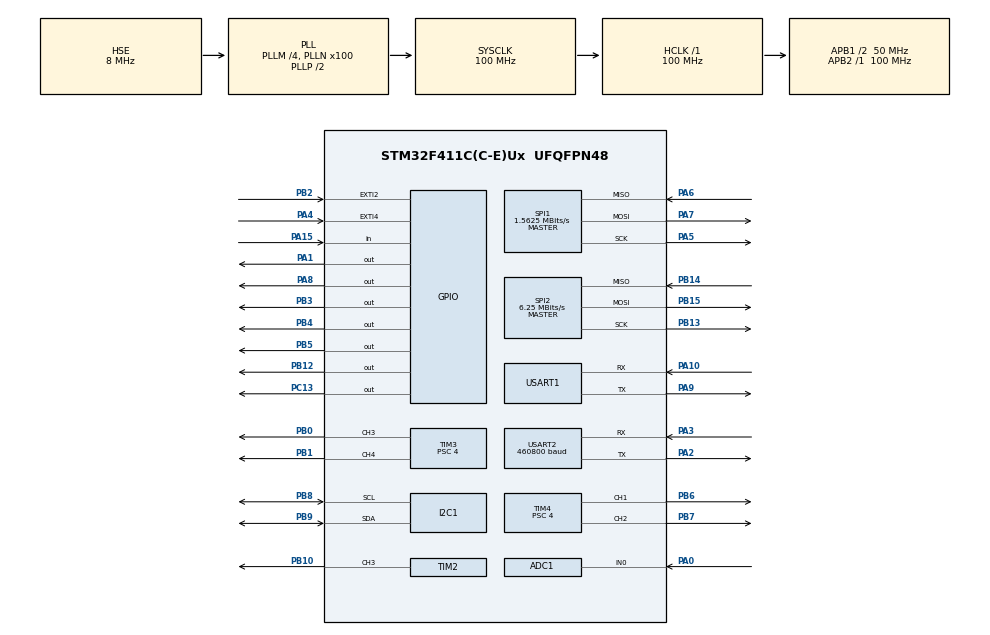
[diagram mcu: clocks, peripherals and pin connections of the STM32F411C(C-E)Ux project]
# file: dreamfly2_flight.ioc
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ADC1.Channel-0\#ChannelRegularConversion=ADC_CHANNEL_0
ADC1.InjNumberOfConversion=0
ADC1.NbrOfConversionFlag=1
ADC1.Rank-0\#ChannelRegularConversion=1
ADC1.SamplingTime-0\#ChannelRegularConversion=ADC_SAMPLETIME_144CYCLES
ADC1.master=1
Dma.Request0=TIM2_CH3/UP
Dma.Request1=USART1_TX
Dma.Request2=USART1_RX
Dma.Request3=USART2_TX
Dma.Request4=USART2_RX
Dma.TIM2_CH3/UP.0.Direction=DMA_MEMORY_TO_PERIPH
Dma.TIM2_CH3/UP.0.FIFOMode=DMA_FIFOMODE_DISABLE
Dma.TIM2_CH3/UP.0.Instance=DMA1_Stream1
Dma.TIM2_CH3/UP.0.MemDataAlignment=DMA_MDATAALIGN_WORD
Dma.TIM2_CH3/UP.0.MemInc=DMA_MINC_ENABLE
Dma.TIM2_CH3/UP.0.Mode=DMA_NORMAL
Dma.TIM2_CH3/UP.0.PeriphDataAlignment=DMA_PDATAALIGN_WORD
Dma.TIM2_CH3/UP.0.PeriphInc=DMA_PINC_DISABLE
Dma.TIM2_CH3/UP.0.Priority=DMA_PRIORITY_LOW
Dma.USART1_RX.2.Direction=DMA_PERIPH_TO_MEMORY
Dma.USART1_RX.2.FIFOMode=DMA_FIFOMODE_DISABLE
Dma.USART1_RX.2.Instance=DMA2_Stream2
Dma.USART1_RX.2.MemDataAlignment=DMA_MDATAALIGN_BYTE
Dma.USART1_RX.2.MemInc=DMA_MINC_ENABLE
Dma.USART1_RX.2.Mode=DMA_NORMAL
Dma.USART1_RX.2.PeriphDataAlignment=DMA_PDATAALIGN_BYTE
Dma.USART1_RX.2.PeriphInc=DMA_PINC_DISABLE
Dma.USART1_RX.2.Priority=DMA_PRIORITY_LOW
Dma.USART1_TX.1.Direction=DMA_MEMORY_TO_PERIPH
Dma.USART1_TX.1.FIFOMode=DMA_FIFOMODE_DISABLE
Dma.USART1_TX.1.Instance=DMA2_Stream7
Dma.USART1_TX.1.MemDataAlignment=DMA_MDATAALIGN_BYTE
Dma.USART1_TX.1.MemInc=DMA_MINC_ENABLE
Dma.USART1_TX.1.Mode=DMA_NORMAL
Dma.USART1_TX.1.PeriphDataAlignment=DMA_PDATAALIGN_BYTE
Dma.USART1_TX.1.PeriphInc=DMA_PINC_DISABLE
Dma.USART1_TX.1.Priority=DMA_PRIORITY_LOW
Dma.USART2_RX.4.Direction=DMA_PERIPH_TO_MEMORY
Dma.USART2_RX.4.FIFOMode=DMA_FIFOMODE_DISABLE
Dma.USART2_RX.4.Instance=DMA1_Stream5
Dma.USART2_RX.4.MemDataAlignment=DMA_MDATAALIGN_BYTE
Dma.USART2_RX.4.MemInc=DMA_MINC_ENABLE
Dma.USART2_RX.4.Mode=DMA_NORMAL
Dma.USART2_RX.4.PeriphDataAlignment=DMA_PDATAALIGN_BYTE
Dma.USART2_RX.4.PeriphInc=DMA_PINC_DISABLE
Dma.USART2_RX.4.Priority=DMA_PRIORITY_LOW
Dma.USART2_TX.3.Direction=DMA_MEMORY_TO_PERIPH
Dma.USART2_TX.3.FIFOMode=DMA_FIFOMODE_DISABLE
Dma.USART2_TX.3.Instance=DMA1_Stream6
Dma.USART2_TX.3.MemDataAlignment=DMA_MDATAALIGN_BYTE
Dma.USART2_TX.3.MemInc=DMA_MINC_ENABLE
Dma.USART2_TX.3.Mode=DMA_NORMAL
Dma.USART2_TX.3.PeriphDataAlignment=DMA_PDATAALIGN_BYTE
Dma.USART2_TX.3.PeriphInc=DMA_PINC_DISABLE
Dma.USART2_TX.3.Priority=DMA_PRIORITY_LOW
FREERTOS.Tasks01=flight_systems,16,256,flight_system_task_entry,As weak,NULL,Dynamic,NULL,NULL;flight_control,40,256,flight_control_task_entry,As weak,NULL,Dynamic,NULL,NULL;flight_sensor,24,256,flight_sensor_task_entry,As weak,NULL,Dynamic,NULL,NULL;flight_debug,8,512,flight_debug_task_entry,As weak,NULL,Dynamic,NULL,NULL;flight_link,32,256,flight_link_task_entry,As weak,NULL,Dynamic,NULL,NULL
I2C1.I2C_Mode=I2C_Fast
Mcu.Family=STM32F4
Mcu.Name=STM32F411C(C-E)Ux
Mcu.Package=UFQFPN48
NVIC.DMA1_Stream1_IRQn=true\:5\:0\:false\:false\:true\:true\:false\:true\:true
NVIC.DMA1_Stream5_IRQn=true\:5\:0\:false\:false\:true\:true\:false\:true\:true
NVIC.DMA1_Stream6_IRQn=true\:5\:0\:false\:false\:true\:true\:false\:true\:true
NVIC.DMA2_Stream2_IRQn=true\:5\:0\:false\:false\:true\:true\:false\:true\:true
NVIC.DMA2_Stream7_IRQn=true\:5\:0\:false\:false\:true\:true\:false\:true\:true
NVIC.EXTI2_IRQn=true\:5\:0\:false\:false\:true\:true\:true\:true\:true
NVIC.EXTI4_IRQn=true\:5\:0\:false\:false\:true\:true\:true\:true\:true
NVIC.PriorityGroup=NVIC_PRIORITYGROUP_4
NVIC.TIM1_TRG_COM_TIM11_IRQn=true\:15\:0\:false\:false\:true\:false\:false\:true\:true
NVIC.TimeBase=TIM1_TRG_COM_TIM11_IRQn
NVIC.TimeBaseIP=TIM11
NVIC.USART1_IRQn=true\:5\:0\:false\:false\:true\:true\:true\:true\:true
NVIC.USART2_IRQn=true\:5\:0\:false\:false\:true\:true\:true\:true\:true
PA0-WKUP.Signal=ADCx_IN0
PA1.PinState=GPIO_PIN_SET
PA1.Signal=GPIO_Output
PA10.Mode=Asynchronous
PA10.Signal=USART1_RX
PA13.Mode=Serial_Wire
PA13.Signal=SYS_JTMS-SWDIO
PA14.Mode=Serial_Wire
PA14.Signal=SYS_JTCK-SWCLK
PA15.Signal=GPIO_Input
PA2.Mode=Asynchronous
PA2.Signal=USART2_TX
PA3.Mode=Asynchronous
PA3.Signal=USART2_RX
PA4.Signal=GPXTI4
PA5.Mode=Full_Duplex_Master
PA5.Signal=SPI1_SCK
PA6.Mode=Full_Duplex_Master
PA6.Signal=SPI1_MISO
PA7.Mode=Full_Duplex_Master
PA7.Signal=SPI1_MOSI
PA8.PinState=GPIO_PIN_RESET
PA8.Signal=GPIO_Output
PA9.Mode=Asynchronous
PA9.Signal=USART1_TX
PB0.Signal=S_TIM3_CH3
PB1.Signal=S_TIM3_CH4
PB10.GPIO_ModeDefaultPP=GPIO_MODE_AF_PP
PB10.GPIO_Speed=GPIO_SPEED_FREQ_HIGH
PB10.Signal=S_TIM2_CH3
PB12.PinState=GPIO_PIN_SET
PB12.Signal=GPIO_Output
PB13.Mode=Full_Duplex_Master
PB13.Signal=SPI2_SCK
PB14.Mode=Full_Duplex_Master
PB14.Signal=SPI2_MISO
PB15.Mode=Full_Duplex_Master
PB15.Signal=SPI2_MOSI
PB2.GPIO_ModeDefaultEXTI=GPIO_MODE_IT_FALLING
PB2.GPIO_PuPd=GPIO_PULLUP
PB2.Signal=GPXTI2
PB3.GPIO_ModeDefaultOutputPP=GPIO_MODE_OUTPUT_OD
PB3.GPIO_PuPd=GPIO_NOPULL
PB3.PinState=GPIO_PIN_SET
PB3.Signal=GPIO_Output
PB4.GPIO_ModeDefaultOutputPP=GPIO_MODE_OUTPUT_OD
PB4.GPIO_PuPd=GPIO_NOPULL
PB4.GPIO_Speed=GPIO_SPEED_FREQ_VERY_HIGH
PB4.PinState=GPIO_PIN_SET
PB4.Signal=GPIO_Output
PB5.GPIO_ModeDefaultOutputPP=GPIO_MODE_OUTPUT_OD
PB5.GPIO_PuPd=GPIO_NOPULL
PB5.GPIO_Speed=GPIO_SPEED_FREQ_VERY_HIGH
PB5.PinState=GPIO_PIN_SET
PB5.Signal=GPIO_Output
PB6.Signal=S_TIM4_CH1
PB7.Signal=S_TIM4_CH2
PB8.Mode=I2C
PB8.Signal=I2C1_SCL
PB9.Mode=I2C
PB9.Signal=I2C1_SDA
PC13-ANTI_TAMP.Signal=GPIO_Output
PH0\ -\ OSC_IN.Mode=HSE-External-Oscillator
PH0\ -\ OSC_IN.Signal=RCC_OSC_IN
PH1\ -\ OSC_OUT.Mode=HSE-External-Oscillator
PH1\ -\ OSC_OUT.Signal=RCC_OSC_OUT
ProjectManager.HeapSize=0x200
ProjectManager.StackSize=0x400
ProjectManager.TargetToolchain=CMake
RCC.48MHZClocksFreq_Value=50000000
RCC.AHBFreq_Value=100000000
RCC.APB1CLKDivider=RCC_HCLK_DIV2
RCC.APB1Freq_Value=50000000
RCC.APB1TimFreq_Value=100000000
RCC.APB2Freq_Value=100000000
RCC.APB2TimFreq_Value=100000000
RCC.CortexFreq_Value=100000000
RCC.HCLKFreq_Value=100000000
RCC.HSE_VALUE=8000000
RCC.HSI_VALUE=16000000
RCC.LSE_VALUE=32768
RCC.PLLM=4
RCC.PLLN=100
RCC.PLLSourceVirtual=RCC_PLLSOURCE_HSE
RCC.SYSCLKFreq_VALUE=100000000
RCC.SYSCLKSource=RCC_SYSCLKSOURCE_PLLCLK
RCC.VCOOutputFreq_Value=200000000
SH.ADCx_IN0.0=ADC1_IN0,IN0
SH.S_TIM2_CH3.0=TIM2_CH3,PWM Generation3 CH3
SH.S_TIM3_CH3.0=TIM3_CH3,PWM Generation3 CH3
SH.S_TIM3_CH4.0=TIM3_CH4,PWM Generation4 CH4
SH.S_TIM4_CH1.0=TIM4_CH1,PWM Generation1 CH1
SH.S_TIM4_CH2.0=TIM4_CH2,PWM Generation2 CH2
SPI1.BaudRatePrescaler=SPI_BAUDRATEPRESCALER_64
SPI1.CLKPhase=SPI_PHASE_1EDGE
SPI1.CLKPolarity=SPI_POLARITY_LOW
SPI1.CalculateBaudRate=1.5625 MBits/s
SPI1.Direction=SPI_DIRECTION_2LINES
SPI1.Mode=SPI_MODE_MASTER
SPI1.VirtualType=VM_MASTER
SPI2.BaudRatePrescaler=SPI_BAUDRATEPRESCALER_8
SPI2.CalculateBaudRate=6.25 MBits/s
SPI2.Direction=SPI_DIRECTION_2LINES
SPI2.Mode=SPI_MODE_MASTER
SPI2.VirtualType=VM_MASTER
TIM2.Channel-PWM\ Generation3\ CH3=TIM_CHANNEL_3
TIM2.Period=124
TIM3.AutoReloadPreload=TIM_AUTORELOAD_PRELOAD_ENABLE
TIM3.Channel-PWM\ Generation3\ CH3=TIM_CHANNEL_3
TIM3.Channel-PWM\ Generation4\ CH4=TIM_CHANNEL_4
TIM3.Period=999
TIM3.Prescaler=4
TIM4.AutoReloadPreload=TIM_AUTORELOAD_PRELOAD_ENABLE
TIM4.Channel-PWM\ Generation1\ CH1=TIM_CHANNEL_1
TIM4.Channel-PWM\ Generation2\ CH2=TIM_CHANNEL_2
TIM4.Period=999
TIM4.Prescaler=4
USART1.VirtualMode=VM_ASYNC
USART2.BaudRate=460800
USART2.VirtualMode=VM_ASYNC
VP_FREERTOS_VS_CMSIS_V2.Mode=CMSIS_V2
VP_SYS_VS_tim11.Mode=TIM11
VP_TIM2_VS_ClockSourceINT.Mode=Internal
VP_TIM3_VS_ClockSourceINT.Mode=Internal
VP_TIM4_VS_ClockSourceINT.Mode=Internal
board=custom

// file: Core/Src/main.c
/* USER CODE BEGIN Header */
/**
  ******************************************************************************
  * @file           : main.c
  * @brief          : Main program body
  ******************************************************************************
  * @attention
  *
  * Copyright (c) 2026 STMicroelectronics.
  * All rights reserved.
  *
  * This software is licensed under terms that can be found in the LICENSE file
  * in the root directory of this software component.
  * If no LICENSE file comes with this software, it is provided AS-IS.
  *
  ******************************************************************************
  */
/* USER CODE END Header */
#include "main.h"
#include "cmsis_os.h"
#include "adc.h"
#include "dma.h"
#include "i2c.h"
#include "spi.h"
#include "tim.h"
#include "usart.h"
#include "gpio.h"

void SystemClock_Config(void);
void MX_FREERTOS_Init(void);

int main(void)
{

  /* MCU Configuration--------------------------------------------------------*/

  /* Reset of all peripherals, Initializes the Flash interface and the Systick. */
  HAL_Init();

  /* Configure the system clock */
  SystemClock_Config();

  /* Initialize all configured peripherals */
  MX_GPIO_Init();
  MX_DMA_Init();
  MX_USART1_UART_Init();
  MX_USART2_UART_Init();
  MX_ADC1_Init();
  MX_I2C1_Init();
  MX_TIM2_Init();
  MX_TIM3_Init();
  MX_TIM4_Init();
  MX_SPI2_Init();
  MX_SPI1_Init();

  /* Init scheduler */
  osKernelInitialize();  /* Call init function for freertos objects (in cmsis_os2.c) */
  MX_FREERTOS_Init();

  /* Start scheduler */
  osKernelStart();

  /* We should never get here as control is now taken by the scheduler */

  /* Infinite loop */
    while (1)
    {

    }
}

void SystemClock_Config(void)
{
  RCC_OscInitTypeDef RCC_OscInitStruct = {0};
  RCC_ClkInitTypeDef RCC_ClkInitStruct = {0};

  /** Configure the main internal regulator output voltage
  */
  __HAL_RCC_PWR_CLK_ENABLE();
  __HAL_PWR_VOLTAGESCALING_CONFIG(PWR_REGULATOR_VOLTAGE_SCALE1);

  /** Initializes the RCC Oscillators according to the specified parameters
  * in the RCC_OscInitTypeDef structure.
  */
  RCC_OscInitStruct.OscillatorType = RCC_OSCILLATORTYPE_HSE;
  RCC_OscInitStruct.HSEState = RCC_HSE_ON;
  RCC_OscInitStruct.PLL.PLLState = RCC_PLL_ON;
  RCC_OscInitStruct.PLL.PLLSource = RCC_PLLSOURCE_HSE;
  RCC_OscInitStruct.PLL.PLLM = 4;
  RCC_OscInitStruct.PLL.PLLN = 100;
  RCC_OscInitStruct.PLL.PLLP = RCC_PLLP_DIV2;
  RCC_OscInitStruct.PLL.PLLQ = 4;
  if (HAL_RCC_OscConfig(&RCC_OscInitStruct) != HAL_OK)
  {
    Error_Handler();
  }

  /** Initializes the CPU, AHB and APB buses clocks
  */
  RCC_ClkInitStruct.ClockType = RCC_CLOCKTYPE_HCLK|RCC_CLOCKTYPE_SYSCLK
                              |RCC_CLOCKTYPE_PCLK1|RCC_CLOCKTYPE_PCLK2;
  RCC_ClkInitStruct.SYSCLKSource = RCC_SYSCLKSOURCE_PLLCLK;
  RCC_ClkInitStruct.AHBCLKDivider = RCC_SYSCLK_DIV1;
  RCC_ClkInitStruct.APB1CLKDivider = RCC_HCLK_DIV2;
  RCC_ClkInitStruct.APB2CLKDivider = RCC_HCLK_DIV1;

  if (HAL_RCC_ClockConfig(&RCC_ClkInitStruct, FLASH_LATENCY_3) != HAL_OK)
  {
    Error_Handler();
  }
}

void HAL_TIM_PeriodElapsedCallback(TIM_HandleTypeDef *htim)
{
  if (htim->Instance == TIM11)
  {
    HAL_IncTick();
  }
}

void Error_Handler(void)
{
    __disable_irq();
    while (1)
    {
    }
}

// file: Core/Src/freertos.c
/* USER CODE BEGIN Header */
/**
  ******************************************************************************
  * File Name          : freertos.c
  * Description        : Code for freertos applications
  ******************************************************************************
  * @attention
  *
  * Copyright (c) 2026 STMicroelectronics.
  * All rights reserved.
  *
  * This software is licensed under terms that can be found in the LICENSE file
  * in the root directory of this software component.
  * If no LICENSE file comes with this software, it is provided AS-IS.
  *
  ******************************************************************************
  */
/* USER CODE END Header */

#include "FreeRTOS.h"
#include "task.h"
#include "main.h"
#include "cmsis_os.h"

/* USER CODE BEGIN Includes */
#include "led.h"
/* USER CODE END Includes */

/* Definitions for flight_systems */
osThreadId_t flight_systemsHandle;
const osThreadAttr_t flight_systems_attributes = {
  .name = "flight_systems",
  .stack_size = 256 * 4,
  .priority = (osPriority_t) osPriorityBelowNormal,
};
/* Definitions for flight_control */
osThreadId_t flight_controlHandle;
const osThreadAttr_t flight_control_attributes = {
  .name = "flight_control",
  .stack_size = 256 * 4,
  .priority = (osPriority_t) osPriorityHigh,
};
/* Definitions for flight_sensor */
osThreadId_t flight_sensorHandle;
const osThreadAttr_t flight_sensor_attributes = {
  .name = "flight_sensor",
  .stack_size = 256 * 4,
  .priority = (osPriority_t) osPriorityNormal,
};
/* Definitions for flight_debug */
osThreadId_t flight_debugHandle;
const osThreadAttr_t flight_debug_attributes = {
  .name = "flight_debug",
  .stack_size = 512 * 4,
  .priority = (osPriority_t) osPriorityLow,
};
/* Definitions for flight_link */
osThreadId_t flight_linkHandle;
const osThreadAttr_t flight_link_attributes = {
  .name = "flight_link",
  .stack_size = 256 * 4,
  .priority = (osPriority_t) osPriorityAboveNormal,
};

void flight_system_task_entry(void *argument);
void flight_control_task_entry(void *argument);
void flight_sensor_task_entry(void *argument);
void flight_debug_task_entry(void *argument);
void flight_link_task_entry(void *argument);

void MX_FREERTOS_Init(void); /* (MISRA C 2004 rule 8.1) */

void MX_FREERTOS_Init(void) {

  /* Create the thread(s) */
  /* creation of flight_systems */
  flight_systemsHandle = osThreadNew(flight_system_task_entry, NULL, &flight_systems_attributes);

  /* creation of flight_control */
  flight_controlHandle = osThreadNew(flight_control_task_entry, NULL, &flight_control_attributes);

  /* creation of flight_sensor */
  flight_sensorHandle = osThreadNew(flight_sensor_task_entry, NULL, &flight_sensor_attributes);

  /* creation of flight_debug */
  flight_debugHandle = osThreadNew(flight_debug_task_entry, NULL, &flight_debug_attributes);

  /* creation of flight_link */
  flight_linkHandle = osThreadNew(flight_link_task_entry, NULL, &flight_link_attributes);

}

__weak void flight_system_task_entry(void *argument)
{
  for(;;)
  {
    osDelay(1);
  }
}

__weak void flight_control_task_entry(void *argument)
{
  for(;;)
  {
    osDelay(1);
  }
}

__weak void flight_sensor_task_entry(void *argument)
{
  for(;;)
  {
    osDelay(1);
  }
}

__weak void flight_debug_task_entry(void *argument)
{
  for(;;)
  {
    osDelay(1);
  }
}

__weak void flight_link_task_entry(void *argument)
{
  for(;;)
  {
    osDelay(1);
  }
}
